# HDSC_HC32F472 register map
Vendor: HDSC; Series: ARMCM4; File version: 1.0
CPU: CM4 r0p1, little endian, MPU, FPU, 4 interrupt priority bits
Registers are 32-bit, read-write, reset 0x0 unless marked. A register's access mark holds for its fields unless they carry their own. Offsets are from the block's base; [hi:lo] are bit positions; {n}, {i} and the like mark numbered series.

## HRPWM1 — desc HRPWM
Base 0x40038800
Same registers: HRPWM2 0x40038C00, HRPWM3 0x40039000, HRPWM4 0x40039400, HRPWM5 0x40039800, HRPWM6 0x40039C00
0x00 CNTER
  [21:0] CNT
0x04 UPDAR
  [21:0] UPDAR
0x40 HRPERAR reset 0x3FFFFF
  [21:0] HRPERAR
0x44 HRPERBR reset 0x3FFFFF
  [21:0] HRPERBR
0x48 HRPERCR reset 0x3FFFFF
  [21:0] HRPERCR
0x80 HRGCMAR reset 0x3FFFFF
  [21:0] HRGCMAR
0x84 HRGCMBR reset 0x3FFFFF
  [21:0] HRGCMBR
0x88 HRGCMCR reset 0x3FFFFF
  [21:0] HRGCMCR
0x8C HRGCMDR reset 0x3FFFFF
  [21:0] HRGCMDR
0x90 HRGCMER reset 0x3FFFFF
  [21:0] HRGCMER
0x94 HRGCMFR reset 0x3FFFFF
  [21:0] HRGCMFR
0xC0 SCMAR reset 0x3FFFC0
  [21:0] SCMAR
0xC4 SCMBR reset 0x3FFFC0
  [21:0] SCMBR
0xC8 SCMCR reset 0x3FFFC0
  [21:0] SCMCR
0xCC SCMDR reset 0x3FFFC0
  [21:0] SCMDR
0xD0 SCMER reset 0x3FFFC0
  [21:0] SCMER
0xD4 SCMFR reset 0x3FFFC0
  [21:0] SCMFR
0x100 HRDTUAR reset 0x3FFFFF
  [21:0] HRDTUAR
0x104 HRDTDAR reset 0x3FFFFF
  [21:0] HRDTDAR
0x108 HRDTUBR reset 0x3FFFFF
  [21:0] HRDTUBR
0x10C HRDTDBR reset 0x3FFFFF
  [21:0] HRDTDBR
0x15C CR
  [3] EN
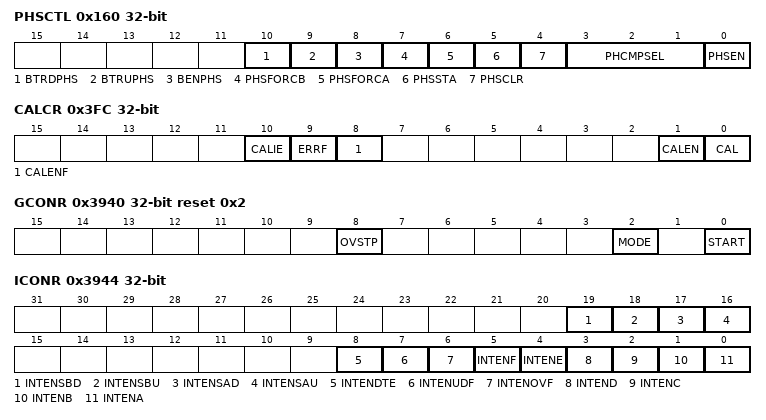
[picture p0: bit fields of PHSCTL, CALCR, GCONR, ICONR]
0x160 PHSCTL
  [10] BTRDPHS, [9] BTRUPHS, [8] BENPHS, [7] PHSFORCB, [6] PHSFORCA, [5] PHSSTA, [4] PHSCLR, [3:1] PHCMPSEL, [0] PHSEN
{0x15C+8i} PHSCMP{i}A reset 0x7FFFFF (i=1..5)
  [22:0] PHSCMP{i}A
{0x160+8i} PHSCMP{i}B reset 0x7FFFFF (i=1..5)
  [22:0] PHSCMP{i}B
0x3FC CALCR
  [10] CALIE, [9] ERRF, [8] CALENF, [1] CALEN, [0] CAL
0x3940 GCONR reset 0x2
  [8] OVSTP, [2] MODE, [0] START
0x3944 ICONR
  [19] INTENSBD, [18] INTENSBU, [17] INTENSAD, [16] INTENSAU, [8] INTENDTE, [7] INTENUDF, [6] INTENOVF, [5] INTENF, [4] INTENE, [3] INTEND, [2] INTENC, [1] INTENB, [0] INTENA
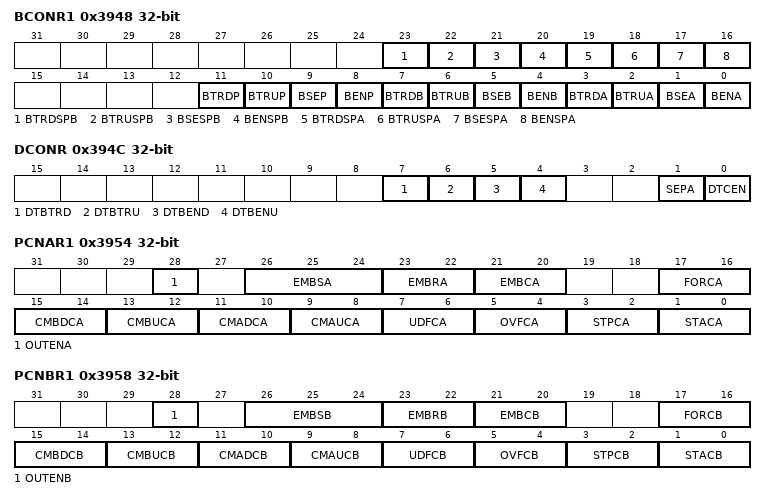
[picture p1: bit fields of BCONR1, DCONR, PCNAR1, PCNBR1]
0x3948 BCONR1
  [23] BTRDSPB, [22] BTRUSPB, [21] BSESPB, [20] BENSPB, [19] BTRDSPA, [18] BTRUSPA, [17] BSESPA, [16] BENSPA, [11] BTRDP, [10] BTRUP, [9] BSEP, [8] BENP, [7] BTRDB, [6] BTRUB, [5] BSEB, [4] BENB, [3] BTRDA, [2] BTRUA, [1] BSEA, [0] BENA
0x394C DCONR
  [7] DTBTRD, [6] DTBTRU, [5] DTBEND, [4] DTBENU, [1] SEPA, [0] DTCEN
0x3954 PCNAR1
  [28] OUTENA, [26:24] EMBSA, [23:22] EMBRA, [21:20] EMBCA, [17:16] FORCA, [15:14] CMBDCA, [13:12] CMBUCA, [11:10] CMADCA, [9:8] CMAUCA, [7:6] UDFCA, [5:4] OVFCA, [3:2] STPCA, [1:0] STACA
0x3958 PCNBR1
  [28] OUTENB, [26:24] EMBSB, [23:22] EMBRB, [21:20] EMBCB, [17:16] FORCB, [15:14] CMBDCB, [13:12] CMBUCB, [11:10] CMADCB, [9:8] CMAUCB, [7:6] UDFCB, [5:4] OVFCB, [3:2] STPCB, [1:0] STACB
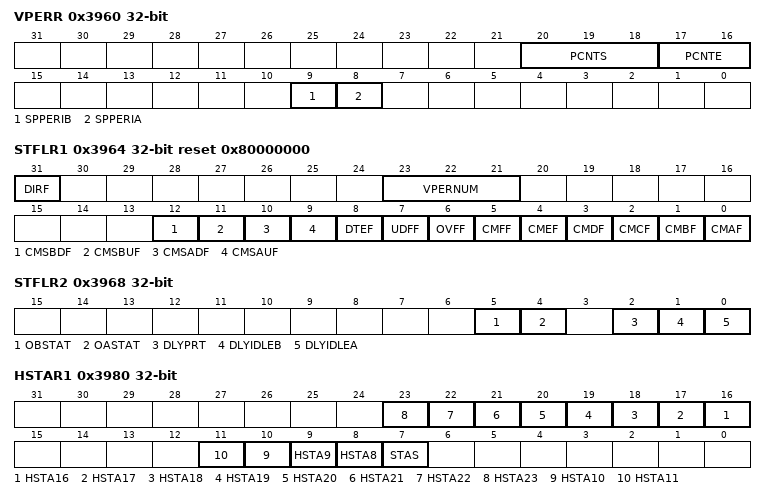
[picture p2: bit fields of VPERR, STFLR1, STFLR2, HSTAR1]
0x3960 VPERR
  [20:18] PCNTS, [17:16] PCNTE, [9] SPPERIB, [8] SPPERIA
0x3964 STFLR1 reset 0x80000000
  [31] DIRF ro, [23:21] VPERNUM ro, [12] CMSBDF, [11] CMSBUF, [10] CMSADF, [9] CMSAUF, [8] DTEF ro, [7] UDFF, [6] OVFF, [5] CMFF, [4] CMEF, [3] CMDF, [2] CMCF, [1] CMBF, [0] CMAF
0x3968 STFLR2
  [5] OBSTAT ro, [4] OASTAT ro, [2] DLYPRT, [1] DLYIDLEB, [0] DLYIDLEA
0x3980 HSTAR1
  [n] HSTA{n} (n=16..23), [n] HSTA{n} (n=8..11), [7] STAS
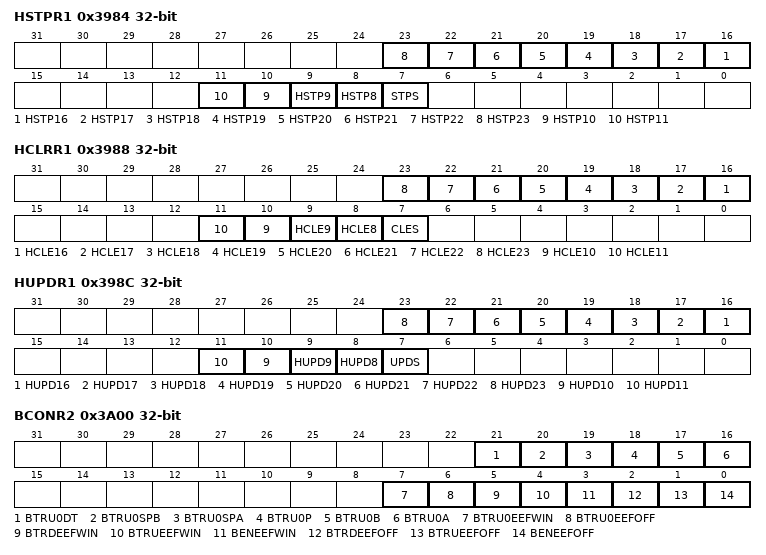
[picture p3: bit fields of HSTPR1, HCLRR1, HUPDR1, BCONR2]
0x3984 HSTPR1
  [n] HSTP{n} (n=16..23), [n] HSTP{n} (n=8..11), [7] STPS
0x3988 HCLRR1
  [n] HCLE{n} (n=16..23), [n] HCLE{n} (n=8..11), [7] CLES
0x398C HUPDR1
  [n] HUPD{n} (n=16..23), [n] HUPD{n} (n=8..11), [7] UPDS
0x3A00 BCONR2
  [21] BTRU0DT, [20] BTRU0SPB, [19] BTRU0SPA, [18] BTRU0P, [17] BTRU0B, [16] BTRU0A, [7] BTRU0EEFWIN, [6] BTRU0EEFOFF, [5] BTRDEEFWIN, [4] BTRUEEFWIN, [3] BENEEFWIN, [2] BTRDEEFOFF, [1] BTRUEEFOFF, [0] BENEEFOFF
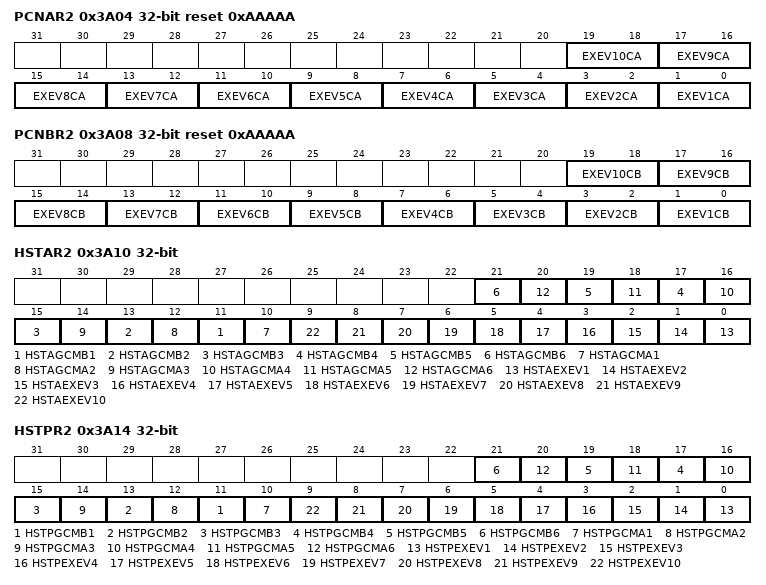
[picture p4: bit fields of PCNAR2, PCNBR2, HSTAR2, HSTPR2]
0x3A04 PCNAR2 reset 0xAAAAA
  [2n-1:2n-2] EXEV{n}CA (n=1..10)
0x3A08 PCNBR2 reset 0xAAAAA
  [2n-1:2n-2] EXEV{n}CB (n=1..10)
0x3A10 HSTAR2
  [2n+9] HSTAGCMB{n} (n=1..6), [2n+8] HSTAGCMA{n} (n=1..6), [n-1] HSTAEXEV{n} (n=1..10)
0x3A14 HSTPR2
  [2n+9] HSTPGCMB{n} (n=1..6), [2n+8] HSTPGCMA{n} (n=1..6), [n-1] HSTPEXEV{n} (n=1..10)
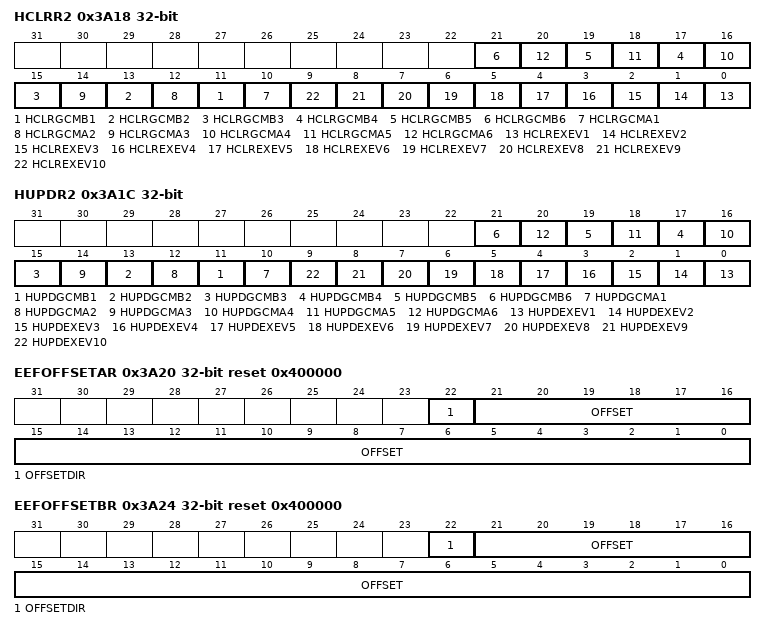
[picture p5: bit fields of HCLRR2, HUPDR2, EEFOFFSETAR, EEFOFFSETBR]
0x3A18 HCLRR2
  [2n+9] HCLRGCMB{n} (n=1..6), [2n+8] HCLRGCMA{n} (n=1..6), [n-1] HCLREXEV{n} (n=1..10)
0x3A1C HUPDR2
  [2n+9] HUPDGCMB{n} (n=1..6), [2n+8] HUPDGCMA{n} (n=1..6), [n-1] HUPDEXEV{n} (n=1..10)
0x3A20 EEFOFFSETAR reset 0x400000
  [22] OFFSETDIR, [21:0] OFFSET
0x3A24 EEFOFFSETBR reset 0x400000
  [22] OFFSETDIR, [21:0] OFFSET
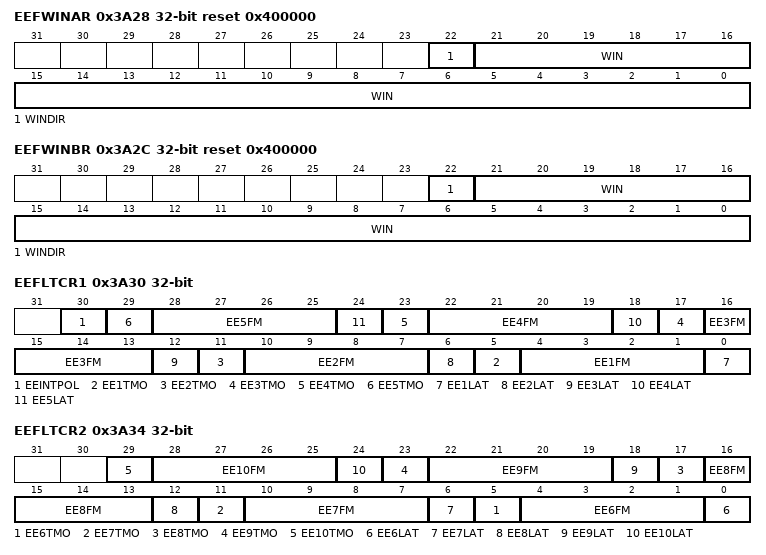
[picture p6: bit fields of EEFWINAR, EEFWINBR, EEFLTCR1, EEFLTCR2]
0x3A28 EEFWINAR reset 0x400000
  [22] WINDIR, [21:0] WIN
0x3A2C EEFWINBR reset 0x400000
  [22] WINDIR, [21:0] WIN
0x3A30 EEFLTCR1
  [30] EEINTPOL, [6n-1] EE{n}TMO (n=1..5), [6n-2:6n-5] EE{n}FM (n=1..5), [6n-6] EE{n}LAT (n=1..5)
0x3A34 EEFLTCR2
  [6n-31] EE{n}TMO (n=6..10), [6n-32:6n-35] EE{n}FM (n=6..10), [6n-36] EE{n}LAT (n=6..10)
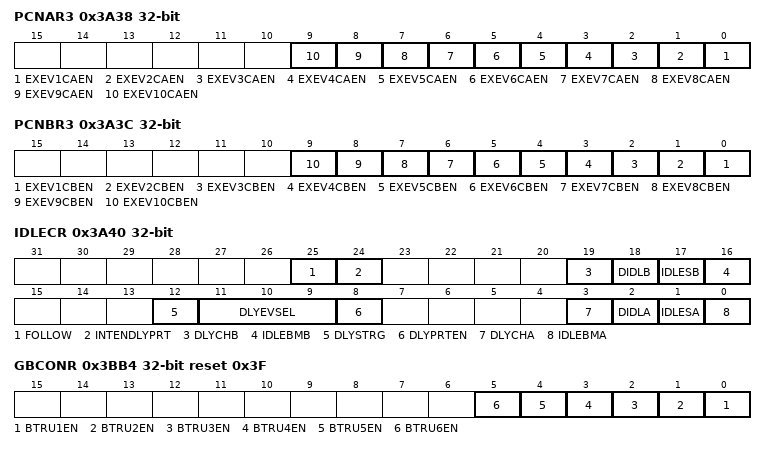
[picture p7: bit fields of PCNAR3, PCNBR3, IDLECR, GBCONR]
0x3A38 PCNAR3
  [n-1] EXEV{n}CAEN (n=1..10)
0x3A3C PCNBR3
  [n-1] EXEV{n}CBEN (n=1..10)
0x3A40 IDLECR
  [25] FOLLOW, [24] INTENDLYPRT, [19] DLYCHB, [18] DIDLB, [17] IDLESB, [16] IDLEBMB, [12] DLYSTRG, [11:9] DLYEVSEL, [8] DLYPRTEN, [3] DLYCHA, [2] DIDLA, [1] IDLESA, [0] IDLEBMA
0x3BB4 GBCONR reset 0x3F
  [n-1] BTRU{n}EN (n=1..6)
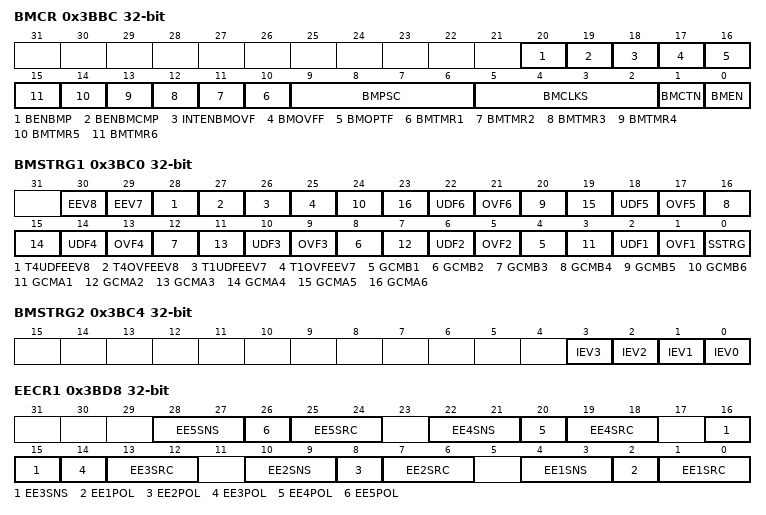
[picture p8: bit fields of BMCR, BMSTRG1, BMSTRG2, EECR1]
0x3BBC BMCR
  [20] BENBMP, [19] BENBMCMP, [18] INTENBMOVF, [17] BMOVFF, [16] BMOPTF, [n+9] BMTMR{n} (n=1..6), [9:6] BMPSC, [5:2] BMCLKS, [1] BMCTN, [0] BMEN
0x3BC0 BMSTRG1
  [30] EEV8, [29] EEV7, [28] T4UDFEEV8, [27] T4OVFEEV8, [26] T1UDFEEV7, [25] T1OVFEEV7, [4n] GCMB{n} (n=1..6), [4n-1] GCMA{n} (n=1..6), [4n-2] UDF{n} (n=1..6), [4n-3] OVF{n} (n=1..6), [0] SSTRG
0x3BC4 BMSTRG2
  [n] IEV{n} (n=0..3)
0x3BC8 BMPERAR reset 0xFFFF
  [15:0] BMPERAR
0x3BCC BMPERBR reset 0xFFFF
  [15:0] BMPERBR
0x3BD0 BMCMAR reset 0xFFFF
  [15:0] BMCMAR
0x3BD4 BMCMBR reset 0xFFFF
  [15:0] BMCMBR
0x3BD8 EECR1
  [6n-2:6n-3] EE{n}SNS (n=1..5), [6n-4] EE{n}POL (n=1..5), [6n-5:6n-6] EE{n}SRC (n=1..5)
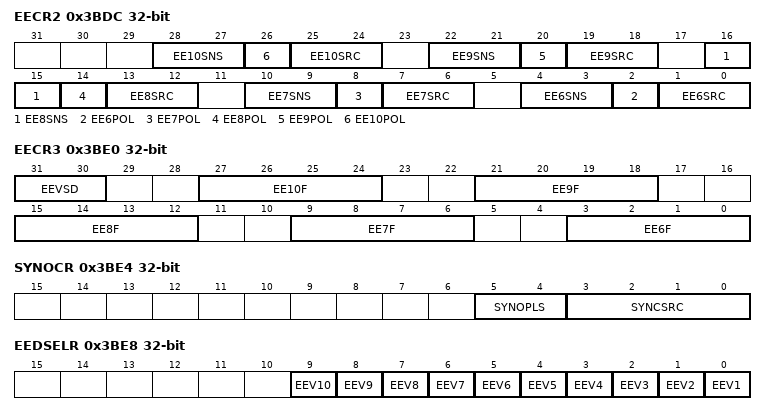
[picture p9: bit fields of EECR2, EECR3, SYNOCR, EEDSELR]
0x3BDC EECR2
  [6n-32:6n-33] EE{n}SNS (n=6..10), [6n-34] EE{n}POL (n=6..10), [6n-35:6n-36] EE{n}SRC (n=6..10)
0x3BE0 EECR3
  [31:30] EEVSD, [6n-33:6n-36] EE{n}F (n=6..10)
0x3BE4 SYNOCR
  [5:4] SYNOPLS, [3:0] SYNCSRC
0x3BE8 EEDSELR
  [n-1] EEV{n} (n=1..10)
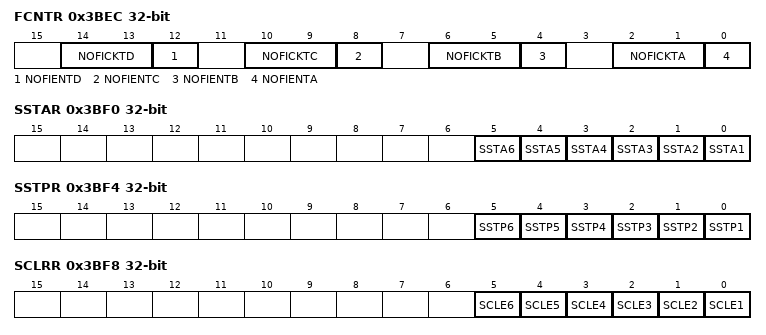
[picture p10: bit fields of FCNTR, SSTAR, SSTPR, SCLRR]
0x3BEC FCNTR
  [14:13] NOFICKTD, [12] NOFIENTD, [10:9] NOFICKTC, [8] NOFIENTC, [6:5] NOFICKTB, [4] NOFIENTB, [2:1] NOFICKTA, [0] NOFIENTA
0x3BF0 SSTAR
  [n-1] SSTA{n} (n=1..6)
0x3BF4 SSTPR
  [n-1] SSTP{n} (n=1..6)
0x3BF8 SCLRR
  [n-1] SCLE{n} (n=1..6)
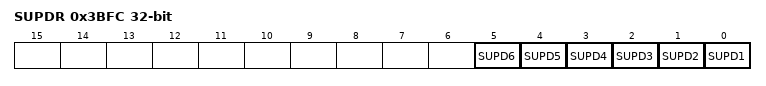
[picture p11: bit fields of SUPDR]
0x3BFC SUPDR
  [n-1] SUPD{n} (n=1..6)
